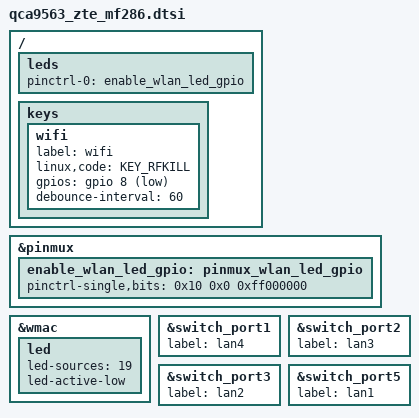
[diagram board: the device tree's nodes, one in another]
// SPDX-License-Identifier: GPL-2.0-or-later OR MIT
// Copyright (c) 2021 Cezary Jackiewicz
// Copyright (c) 2021, 2022 Lech Perczak
#include "qca9563_zte_mf28x.dtsi"

/ {
	leds {
		pinctrl-names = "default";
		pinctrl-0 = <&enable_wlan_led_gpio>;
	};

	keys {
		wifi {
			label = "wifi";
			linux,code = <KEY_RFKILL>;
			gpios = <&gpio 8 GPIO_ACTIVE_LOW>;
			debounce-interval = <60>;
		};
	};
};

&pinmux {
	enable_wlan_led_gpio: pinmux_wlan_led_gpio {
		pinctrl-single,bits = <0x10 0x0 0xff000000>;
	};
};

&wmac {
	led {
		led-sources = <19>;
		led-active-low;
	};
};

&switch_port1 {
	status = "okay";
	label = "lan4";
};

&switch_port2 {
	status = "okay";
	label = "lan3";
};

&switch_port3 {
	status = "okay";
	label = "lan2";
};

&switch_port5 {
	status = "okay";
	label = "lan1";
};
